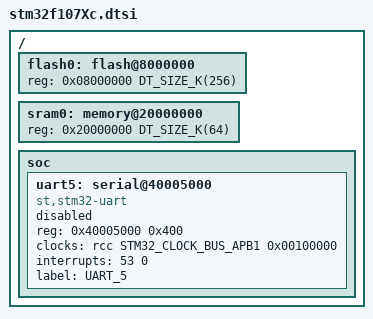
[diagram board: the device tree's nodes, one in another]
/*
 * Copyright (c) 2018 Linaro Limited
 *
 * SPDX-License-Identifier: Apache-2.0
 */

#include <mem.h>
#include <st/f1/stm32f107.dtsi>

/ {
	flash0: flash@8000000 {
		reg = <0x08000000 DT_SIZE_K(256)>;
	};

	sram0: memory@20000000 {
		reg = <0x20000000 DT_SIZE_K(64)>;
	};

	soc {
		uart5: serial@40005000 {
				compatible = "st,stm32-uart";
				reg = <0x40005000 0x400>;
				clocks = <&rcc STM32_CLOCK_BUS_APB1 0x00100000>;
				interrupts = <53 0>;
				status = "disabled";
				label = "UART_5";
		};
	};
};
